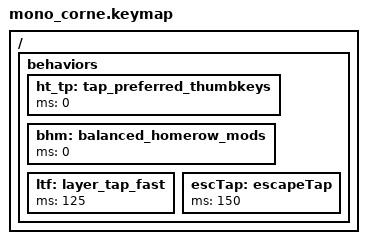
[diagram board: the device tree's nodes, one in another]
/*
 * Mono Corne keyboard keymap
 *
 * This keymap defines Mono Corne-specific configurations that extend the base
 * keymap.
 */

#include "base.keymap"

/ {
  behaviors {
  ht_tp:
    tap_preferred_thumbkeys {
      tapping - term - ms = <150>;
      quick - tap - ms = <0>;
    };

  bhm:
    balanced_homerow_mods {
      tapping - term - ms = <150>;
      quick - tap - ms = <0>;
    };

  ltf:
    layer_tap_fast {
      tapping - term - ms = <125>;
      quick - tap - ms = <125>;
      require - prior - idle - ms = <125>;
    };

  escTap:
    escapeTap { tapping - term - ms = <150>; };
  };
};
